# STM32U366 register map
File version: 1.0
CPU: CM33 r0p1, little endian, MPU, FPU, 4 interrupt priority bits
Registers are 32-bit, read-write, reset 0x0 unless marked. A register's access mark holds for its fields unless they carry their own. Offsets are from the block's base; [hi:lo] are bit positions; {n}, {i} and the like mark numbered series.

## GPIOA — GPIOA address block description
Base 0x42020000
Same registers: SEC_GPIOA 0x52020000
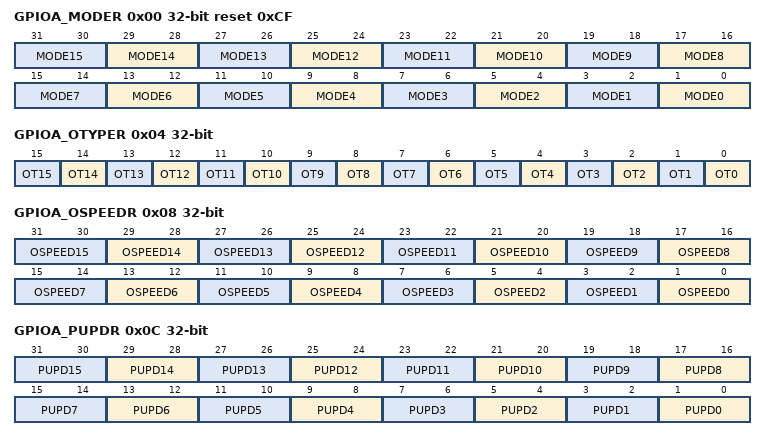
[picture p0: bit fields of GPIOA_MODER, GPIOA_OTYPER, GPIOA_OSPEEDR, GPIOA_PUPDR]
0x00 GPIOA_MODER reset 0xCF — GPIO port mode register
  [all] fields
    0=Input mode; 1=General purpose output mode; 2=Alternate function mode; 3=Analog mode (reset state)
  [2n+1:2n] MODE{n} (n=0..15) — Port x I/O pin y mode configuration
0x04 GPIOA_OTYPER — GPIO port output type register
  [all] fields
    0=Output push-pull (reset state); 1=Output open-drain
  [n] OT{n} (n=0..15) — Port x I/O pin y output type configuration
0x08 GPIOA_OSPEEDR — GPIO port output speed register
  [all] fields
    0=Low speed; 1=Medium speed; 2=High speed; 3=Very-high speed
  [2n+1:2n] OSPEED{n} (n=0..15) — Port x I/O pin y output speed configuration
0x0C GPIOA_PUPDR — GPIO port pull-up/pull-down register
  [all] fields
    0=No pull-up or pull-down; 1=Pull-up; 2=Pull-down
  [2n+1:2n] PUPD{n} (n=0..15) — Port x I/O pin y pull-up/pull-down configuration
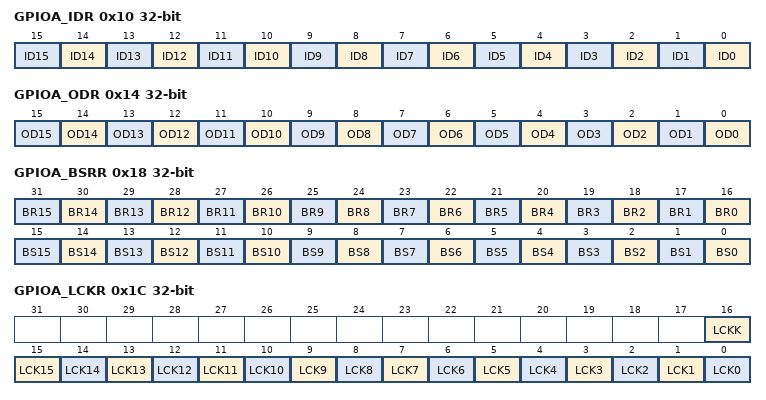
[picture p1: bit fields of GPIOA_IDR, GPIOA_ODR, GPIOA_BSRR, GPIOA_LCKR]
0x10 GPIOA_IDR ro (reset mask 0xFFFF0000) — GPIO port input data register
  [n] ID{n} (n=0..15) — Port x I/O pin y input data
0x14 GPIOA_ODR — GPIO port output data register
  [n] OD{n} (n=0..15) — Port x I/O pin y output data
0x18 GPIOA_BSRR wo — GPIO port bit set/reset register
  [n+16] BR{n} (n=0..15) — Port x I/O pin y output reset
    0=No action on the corresponding ODy bit; 1=Resets the corresponding ODy bit
  [n] BS{n} (n=0..15) — Port x I/O pin y output set
    0=No action on the corresponding ODy bit; 1=Sets the corresponding ODy bit
0x1C GPIOA_LCKR — GPIO port configuration lock register
  [16] LCKK — Lock key
    0=Port configuration lock key not active; 1=Port configuration lock key active
  [n] LCK{n} (n=0..15) — Port x I/O pin y lock
    0=Port configuration not locked; 1=Port configuration locked
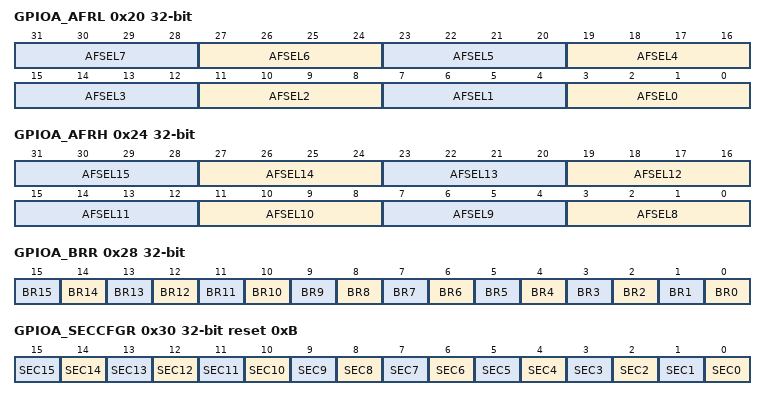
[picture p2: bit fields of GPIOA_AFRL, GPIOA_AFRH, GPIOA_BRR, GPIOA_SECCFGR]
0x20 GPIOA_AFRL — GPIO alternate function low register
  [all] fields
    {v}=AF{v} (v=0..15)
  [4n+3:4n] AFSEL{n} (n=0..7) — Port x I/O pin y alternate function selection for
0x24 GPIOA_AFRH — GPIO alternate function high register
  [all] fields
    {v}=AF{v} (v=0..15)
  [4n-29:4n-32] AFSEL{n} (n=8..15) — Port x I/O pin y alternate function selection
0x28 GPIOA_BRR wo — GPIO port bit reset register
  [all] fields
    0=No action on the corresponding ODy bit; 1=Reset the corresponding ODy bit
  [n] BR{n} (n=0..15) — Port x I/O pin y output reset
0x30 GPIOA_SECCFGR reset 0xB — GPIO secure configuration register
  [all] fields
    0=The I/O pin is nonsecure; 1=The I/O pin is secure
  [n] SEC{n} (n=0..15) — Port x I/O pin y security configuration

## GPIOB — GPIOB address block description
Base 0x42020400
Same registers: SEC_GPIOB 0x52020400
Registers as GPIOA (with GPIOA read as GPIOB).

## GPIOC — GPIOC address block description
Base 0x42020800
Same registers: SEC_GPIOC 0x52020800
Registers as GPIOA (with GPIOA read as GPIOC).

## GPIOD — GPIOD address block description
Base 0x42020C00
Same registers: SEC_GPIOD 0x52020C00
Registers as GPIOA (with GPIOA read as GPIOD).

## GPIOE — GPIOE address block description
Base 0x42021000
Same registers: SEC_GPIOE 0x52021000
Registers as GPIOA (with GPIOA read as GPIOE).

## GPIOH — GPIOH address block description
Base 0x42021C00
Same registers: SEC_GPIOH 0x52021C00
Registers as GPIOA (with GPIOA read as GPIOH).

## GTZC1_MPCBB1 — MPCBB1 Address block
Base 0x40032C00
Same registers: SEC_GTZC1_MPCBB1 0x50032C00
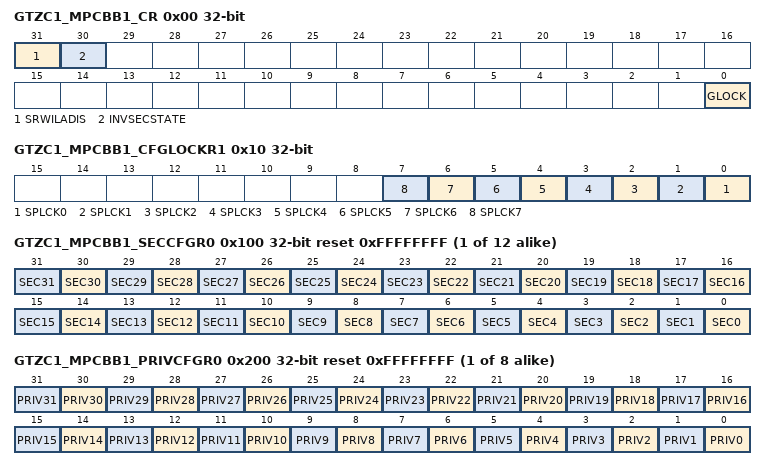
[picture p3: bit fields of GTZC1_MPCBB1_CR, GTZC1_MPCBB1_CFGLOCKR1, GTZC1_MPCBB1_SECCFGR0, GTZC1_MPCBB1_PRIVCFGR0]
0x00 GTZC1_MPCBB1_CR — GTZC1 SRAM1 MPCBB control register
  [31] SRWILADIS — Secure read/write illegal access disable
    0=Enabled, secure read/write access not allowed on nonsecure SRAM block; 1=Disabled, secure read/write access allowed on nonsecure SRAM block
  [30] INVSECSTATE — SRAM1 clock security state
    0=SRAM clocks are secure if a secure area exists in the MPCBB, and nonsecure if there is no secure area; 1=SRAM clocks are nonsecure even if a secure area exists in the MPCBB, and secure even if no secure block is set in the MPCBB
  [0] GLOCK — Lock the control register of the MPCBB until next reset
    0=Control register not locked; 1=Control register locked
0x10 GTZC1_MPCBB1_CFGLOCKR1 — GTZC1 SRAM1 MPCBB configuration lock register 1
  [all] fields
    0=MPCBB1_SECCFGRi and MPCBB1_PRIVCFGRi can be written; 1=Writes to MPCBB1_SECCFGRi and MPCBB1_PRIVCFGRi are ignored
  [n] SPLCK{n} (n=0..7) — Security/privilege configuration lock for super-block i
{0x100+4i} GTZC1_MPCBB1_SECCFGR{i} reset 0xFFFFFFFF (i=0..11) — GTZC1 SRAM1 MPCBB security configuration for super-block {i} register
  [all] fields
    0=Nonsecure access only to block i, belonging to super-block x; 1=Secure access only to block i, belonging to super-block x
  [n] SEC{n} (n=0..31) — Security configuration for block i
{0x200+4i} GTZC1_MPCBB1_PRIVCFGR{i} reset 0xFFFFFFFF (i=0..7) — GTZC1 SRAM1 MPCBB privileged configuration for super-block {i} register
  [all] fields
    0=Privileged and unprivileged access to block i, belonging to super-block x; 1=Only privileged access to block i, belonging to super-block x
  [n] PRIV{n} (n=0..31) — Privileged configuration for block i, belonging to super-block x
